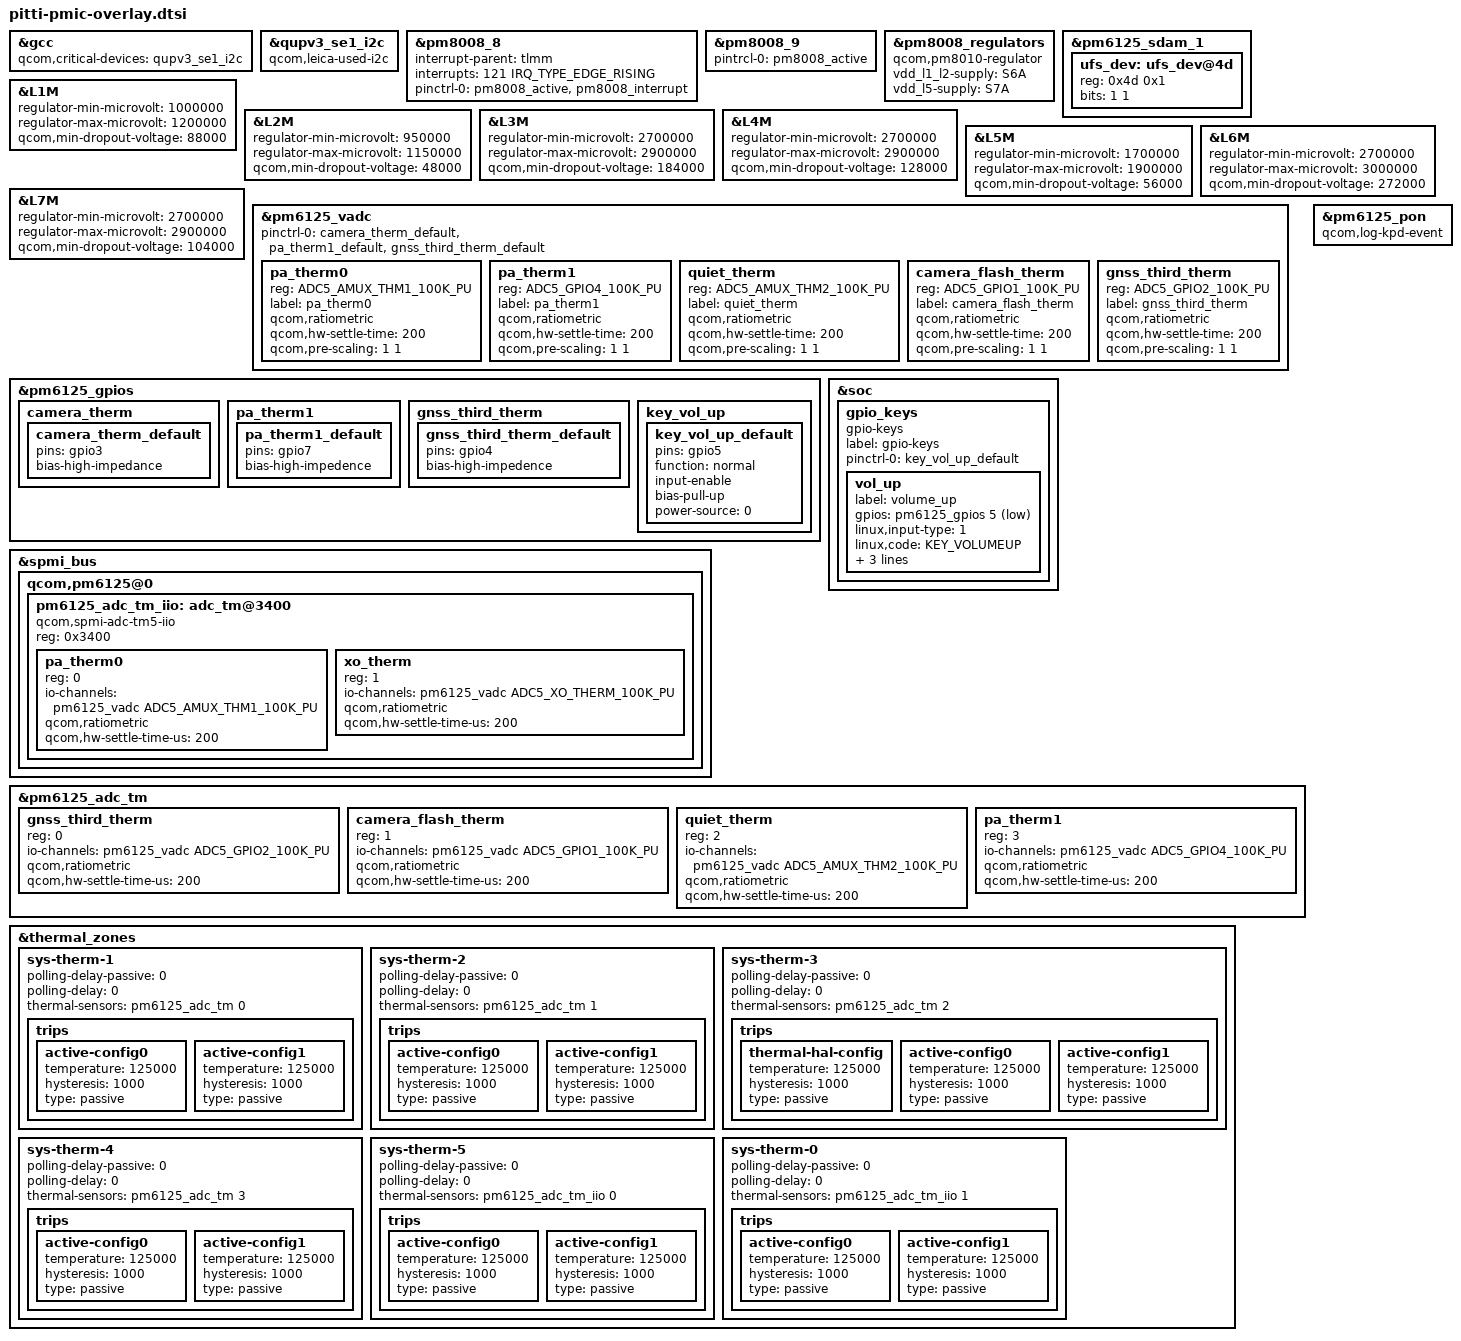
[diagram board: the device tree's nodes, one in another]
#include <dt-bindings/gpio/gpio.h>
#include "pm6125.dtsi"

/*
 * Each QUP device that's a parent to PMIC must be listed
 * as a critical device to GCC.
 */
&gcc {
	qcom,critical-devices = <&qupv3_se1_i2c>;
};

&qupv3_se1_i2c {
	status = "ok";
	qcom,leica-used-i2c;
	#include "pm8008.dtsi"
};

&pm8008_8 {
	/* PM8008 IRQ STAT */
	interrupt-parent = <&tlmm>;
	interrupts = <121 IRQ_TYPE_EDGE_RISING>;
	pinctrl-names = "default";
	pinctrl-0 = <&pm8008_active &pm8008_interrupt>;
};

&pm8008_9 {
	pintrcl-0 = <&pm8008_active>;
};

&pm8008_regulators {
	compatible = "qcom,pm8010-regulator";
	vdd_l1_l2-supply = <&S6A>;
	vdd_l5-supply = <&S7A>;
};

&pm6125_sdam_1 {
	ufs_dev: ufs_dev@4d {
		reg = <0x4d 0x1>;
		bits = <1 1>;
	};
};

&L1M {
	regulator-min-microvolt = <1000000>;
	regulator-max-microvolt = <1200000>;
	qcom,min-dropout-voltage = <88000>;
};

&L2M {
	regulator-min-microvolt = <950000>;
	regulator-max-microvolt = <1150000>;
	qcom,min-dropout-voltage = <48000>;
};

&L3M {
	regulator-min-microvolt = <2700000>;
	regulator-max-microvolt = <2900000>;
	qcom,min-dropout-voltage = <184000>;
};

&L4M {
	regulator-min-microvolt = <2700000>;
	regulator-max-microvolt = <2900000>;
	qcom,min-dropout-voltage = <128000>;
};

&L5M {
	regulator-min-microvolt = <1700000>;
	regulator-max-microvolt = <1900000>;
	qcom,min-dropout-voltage = <56000>;
};

&L6M {
	regulator-min-microvolt = <2700000>;
	regulator-max-microvolt = <3000000>;
	qcom,min-dropout-voltage = <272000>;
};

&L7M {
	regulator-min-microvolt = <2700000>;
	regulator-max-microvolt = <2900000>;
	qcom,min-dropout-voltage = <104000>;
};

&pm6125_vadc {
	#address-cells = <1>;
	#size-cells = <0>;
	pinctrl-names = "default";
	pinctrl-0 = <&camera_therm_default &pa_therm1_default &gnss_third_therm_default>;

	pa_therm0 {
		reg = <ADC5_AMUX_THM1_100K_PU>;
		label = "pa_therm0";
		qcom,ratiometric;
		qcom,hw-settle-time = <200>;
		qcom,pre-scaling = <1 1>;
	};

	pa_therm1 {
		reg = <ADC5_GPIO4_100K_PU>;
		label = "pa_therm1";
		qcom,ratiometric;
		qcom,hw-settle-time = <200>;
		qcom,pre-scaling = <1 1>;
	};

	quiet_therm {
		reg = <ADC5_AMUX_THM2_100K_PU>;
		label = "quiet_therm";
		qcom,ratiometric;
		qcom,hw-settle-time = <200>;
		qcom,pre-scaling = <1 1>;
	};

	camera_flash_therm {
		reg = <ADC5_GPIO1_100K_PU>;
		label = "camera_flash_therm";
		qcom,ratiometric;
		qcom,hw-settle-time = <200>;
		qcom,pre-scaling = <1 1>;
	};

	gnss_third_therm {
		reg = <ADC5_GPIO2_100K_PU>;
		label = "gnss_third_therm";
		qcom,ratiometric;
		qcom,hw-settle-time = <200>;
		qcom,pre-scaling = <1 1>;
	};
};

&pm6125_gpios {
	camera_therm {
		camera_therm_default: camera_therm_default {
			pins = "gpio3";
			bias-high-impedance;
		};
	};

	pa_therm1 {
		pa_therm1_default: pa_therm1_default {
			pins = "gpio7";
			bias-high-impedence;
		};
	};

	gnss_third_therm {
		gnss_third_therm_default: gnss_third_therm_default {
			pins = "gpio4";
			bias-high-impedence;
		};
	};

	key_vol_up {
		key_vol_up_default: key_vol_up_default {
			pins = "gpio5";
			function = "normal";
			input-enable;
			bias-pull-up;
			power-source = <0>;
		};
	};
};

&spmi_bus {
	qcom,pm6125@0 {
		pm6125_adc_tm_iio: adc_tm@3400 {
			compatible = "qcom,spmi-adc-tm5-iio";
			reg = <0x3400>;
			#thermal-sensor-cells = <1>;
			#address-cells = <1>;
			#size-cells = <0>;

			pa_therm0 {
				reg = <0>;
				io-channels = <&pm6125_vadc ADC5_AMUX_THM1_100K_PU>;
				qcom,ratiometric;
				qcom,hw-settle-time-us = <200>;
			};

			xo_therm {
				reg = <1>;
				io-channels = <&pm6125_vadc ADC5_XO_THERM_100K_PU>;
				qcom,ratiometric;
				qcom,hw-settle-time-us = <200>;
			};
		};
	};
};

&soc {
	gpio_keys {
		compatible = "gpio-keys";
		label = "gpio-keys";

		pinctrl-names = "default";
		pinctrl-0 = <&key_vol_up_default>;

		vol_up {
			label = "volume_up";
			gpios = <&pm6125_gpios 5 GPIO_ACTIVE_LOW>;
			linux,input-type = <1>;
			linux,code = <KEY_VOLUMEUP>;
			gpio-key,wakeup;
			debounce-interval = <15>;
			linux,can-disable;
		};
	};
};

&pm6125_adc_tm {
	#address-cells = <1>;
	#size-cells = <0>;
/* Channel nodes */
	gnss_third_therm {
		reg = <0>;
		io-channels = <&pm6125_vadc ADC5_GPIO2_100K_PU>;
		qcom,ratiometric;
		qcom,hw-settle-time-us = <200>;
	};

	camera_flash_therm {
		reg = <1>;
		io-channels = <&pm6125_vadc ADC5_GPIO1_100K_PU>;
		qcom,ratiometric;
		qcom,hw-settle-time-us = <200>;
	};

	quiet_therm {
		reg = <2>;
		io-channels = <&pm6125_vadc ADC5_AMUX_THM2_100K_PU>;
		qcom,ratiometric;
		qcom,hw-settle-time-us = <200>;
	};

	pa_therm1 {
		reg = <3>;
		io-channels = <&pm6125_vadc ADC5_GPIO4_100K_PU>;
		qcom,ratiometric;
		qcom,hw-settle-time-us = <200>;
	};

};

&pm6125_pon {
	qcom,log-kpd-event;
};

&thermal_zones {
	sys-therm-1 {
		polling-delay-passive = <0>;
		polling-delay = <0>;
		thermal-sensors = <&pm6125_adc_tm 0>;
		trips {
			active-config0 {
				temperature = <125000>;
				hysteresis = <1000>;
				type = "passive";
			};

			active-config1 {
				temperature = <125000>;
				hysteresis = <1000>;
				type = "passive";
			};
		};
	};

	sys-therm-2 {
		polling-delay-passive = <0>;
		polling-delay = <0>;
		thermal-sensors = <&pm6125_adc_tm 1>;
		trips {
			active-config0 {
				temperature = <125000>;
				hysteresis = <1000>;
				type = "passive";
			};

			active-config1 {
				temperature = <125000>;
				hysteresis = <1000>;
				type = "passive";
			};
		};
	};

	sys-therm-3 {
		polling-delay-passive = <0>;
		polling-delay = <0>;
		thermal-sensors = <&pm6125_adc_tm 2>;
		trips {
			thermal-hal-config {
				temperature = <125000>;
				hysteresis = <1000>;
				type = "passive";
			};

			active-config0 {
				temperature = <125000>;
				hysteresis = <1000>;
				type = "passive";
			};

			active-config1 {
				temperature = <125000>;
				hysteresis = <1000>;
				type = "passive";
			};
		};
	};

	sys-therm-4 {
		polling-delay-passive = <0>;
		polling-delay = <0>;
		thermal-sensors = <&pm6125_adc_tm 3>;
		trips {
			active-config0 {
				temperature = <125000>;
				hysteresis = <1000>;
				type = "passive";
			};

			active-config1 {
				temperature = <125000>;
				hysteresis = <1000>;
				type = "passive";
			};
		};
	};

	sys-therm-5 {
		polling-delay-passive = <0>;
		polling-delay = <0>;
		thermal-sensors = <&pm6125_adc_tm_iio 0>;
		trips {
			active-config0 {
				temperature = <125000>;
				hysteresis = <1000>;
				type = "passive";
			};

			active-config1 {
				temperature = <125000>;
				hysteresis = <1000>;
				type = "passive";
			};
		};
	};

	sys-therm-0 {
		polling-delay-passive = <0>;
		polling-delay = <0>;
		thermal-sensors = <&pm6125_adc_tm_iio 1>;
		trips {
			active-config0 {
				temperature = <125000>;
				hysteresis = <1000>;
				type = "passive";
			};

			active-config1 {
				temperature = <125000>;
				hysteresis = <1000>;
				type = "passive";
			};
		};
	};
};
